# SWM341 register map
File version: 1.0
CPU: CM0 r1p0, little endian, MPU, FPU, 2 interrupt priority bits
Registers are 32-bit, read-write, no defined reset value unless marked. A register's access mark holds for its fields unless they carry their own. Offsets are from the block's base; [hi:lo] are bit positions; lines under a group give offsets from that group; {n}, {i} and the like mark numbered series; 'fields as' and 'values as' point back to an identical list.

## USBH — Registers group
Base 0x40005000; alternate view of USBD
{0x0+4i} TXBUF[{i}] (i=0..255)
{0x4000+4i} RXBUF[{i}] (i=0..255)
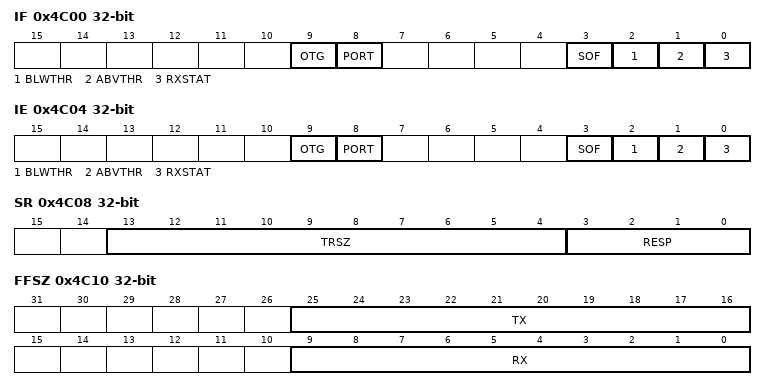
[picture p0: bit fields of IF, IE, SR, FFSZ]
0x4C00 IF
  [9] OTG, [8] PORT, [3] SOF, [2] BLWTHR, [1] ABVTHR, [0] RXSTAT
0x4C04 IE
  [9] OTG, [8] PORT, [3] SOF, [2] BLWTHR, [1] ABVTHR, [0] RXSTAT
0x4C08 SR
  [13:4] TRSZ, [3:0] RESP
0x4C0C CR
  [0] FLUSHFF
0x4C10 FFSZ
  [25:16] TX, [9:0] RX
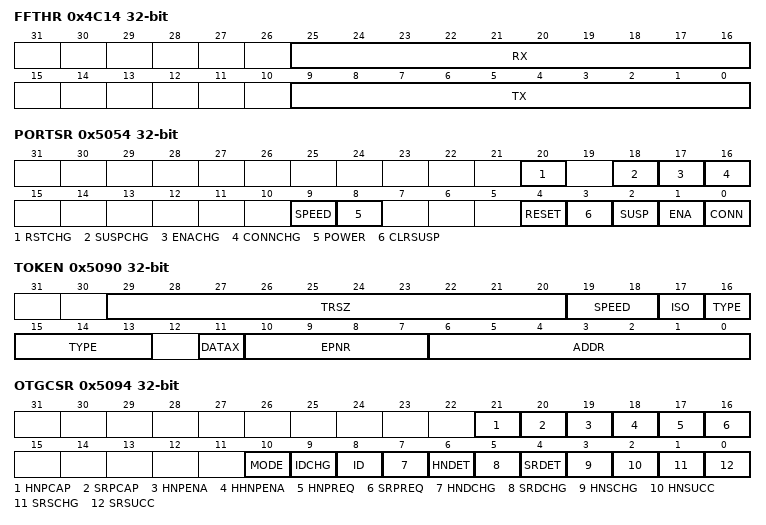
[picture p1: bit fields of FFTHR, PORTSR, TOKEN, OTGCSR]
0x4C14 FFTHR
  [25:16] RX, [9:0] TX
0x4C18 TXTRSZ
0x5034 FRAMEIV
0x5038 FRAMERM
0x503C FRAMENR
0x5054 PORTSR
  [20] RSTCHG, [18] SUSPCHG, [17] ENACHG, [16] CONNCHG, [9] SPEED, [8] POWER, [4] RESET, [3] CLRSUSP, [2] SUSP, [1] ENA, [0] CONN
0x5090 TOKEN
  [29:20] TRSZ, [19:18] SPEED, [17] ISO, [16:13] TYPE, [11] DATAX, [10:7] EPNR, [6:0] ADDR
0x5094 OTGCSR
  [21] HNPCAP, [20] SRPCAP, [19] HNPENA, [18] HHNPENA, [17] HNPREQ, [16] SRPREQ, [10] MODE, [9] IDCHG, [8] ID, [7] HNDCHG, [6] HNDET, [5] SRDCHG, [4] SRDET, [3] HNSCHG, [2] HNSUCC, [1] SRSCHG, [0] SRSUCC

## SDIO — Registers group
Base 0x40001800
0x00 DMA_MEM_ADDR
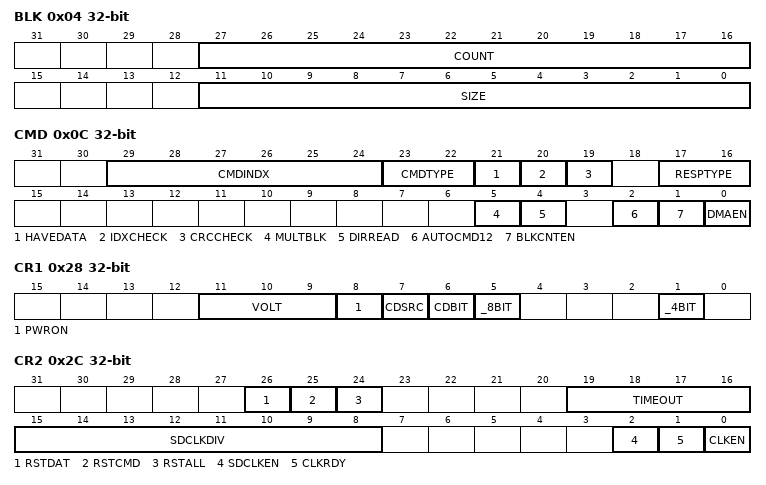
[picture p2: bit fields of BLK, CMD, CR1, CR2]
0x04 BLK
  [27:16] COUNT, [11:0] SIZE
0x08 ARG
0x0C CMD
  [29:24] CMDINDX, [23:22] CMDTYPE, [21] HAVEDATA, [20] IDXCHECK, [19] CRCCHECK, [17:16] RESPTYPE, [5] MULTBLK, [4] DIRREAD, [2] AUTOCMD12, [1] BLKCNTEN, [0] DMAEN
{0x10+4i} RESP[{i}] (i=0..3)
0x20 DATA
0x24 STAT
0x28 CR1
  [11:9] VOLT, [8] PWRON, [7] CDSRC, [6] CDBIT, [5] _8BIT, [1] _4BIT
0x2C CR2
  [26] RSTDAT, [25] RSTCMD, [24] RSTALL, [19:16] TIMEOUT, [15:8] SDCLKDIV, [2] SDCLKEN, [1] CLKRDY, [0] CLKEN
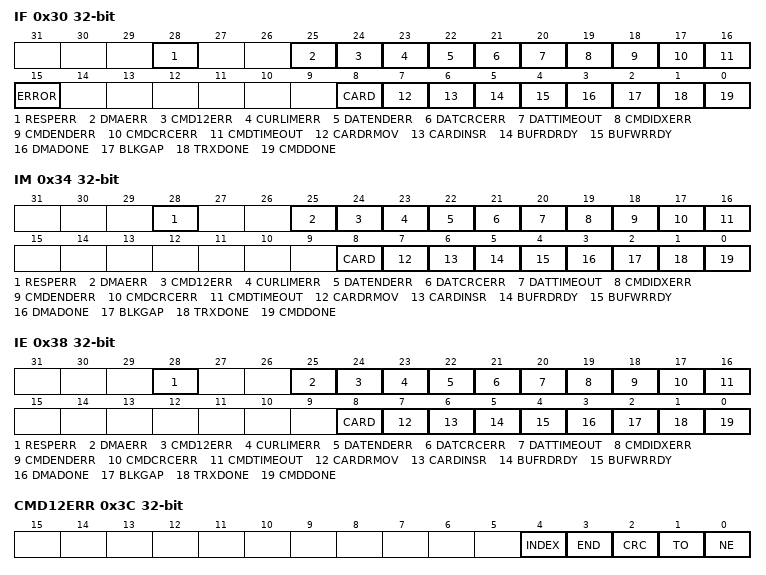
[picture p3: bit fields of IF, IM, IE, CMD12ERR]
0x30 IF
  [28] RESPERR, [25] DMAERR, [24] CMD12ERR, [23] CURLIMERR, [22] DATENDERR, [21] DATCRCERR, [20] DATTIMEOUT, [19] CMDIDXERR, [18] CMDENDERR, [17] CMDCRCERR, [16] CMDTIMEOUT, [15] ERROR, [8] CARD, [7] CARDRMOV, [6] CARDINSR, [5] BUFRDRDY, [4] BUFWRRDY, [3] DMADONE, [2] BLKGAP, [1] TRXDONE, [0] CMDDONE
0x34 IM
  [28] RESPERR, [25] DMAERR, [24] CMD12ERR, [23] CURLIMERR, [22] DATENDERR, [21] DATCRCERR, [20] DATTIMEOUT, [19] CMDIDXERR, [18] CMDENDERR, [17] CMDCRCERR, [16] CMDTIMEOUT, [8] CARD, [7] CARDRMOV, [6] CARDINSR, [5] BUFRDRDY, [4] BUFWRRDY, [3] DMADONE, [2] BLKGAP, [1] TRXDONE, [0] CMDDONE
0x38 IE
  fields as IM
0x3C CMD12ERR
  [4] INDEX, [3] END, [2] CRC, [1] TO, [0] NE

## SDRAMC — Registers group
Base 0x88000000
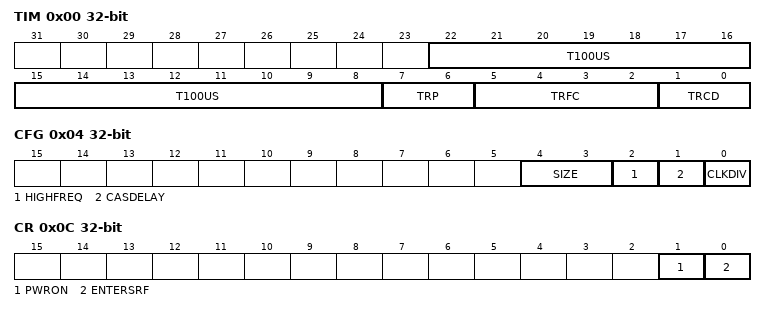
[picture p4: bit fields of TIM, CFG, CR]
0x00 TIM
  [22:8] T100US, [7:6] TRP, [5:2] TRFC, [1:0] TRCD
0x04 CFG
  [4:3] SIZE, [2] HIGHFREQ, [1] CASDELAY, [0] CLKDIV
0x08 T64
0x0C CR
  [1] PWRON, [0] ENTERSRF
0x10 SR

## DMA — Registers group
Base 0x40000800
0x00 EN
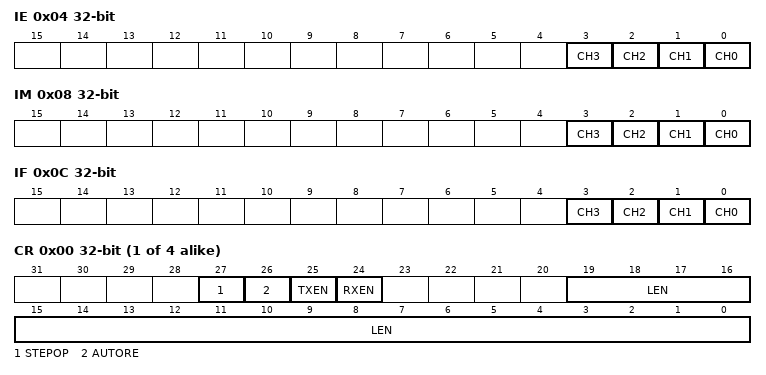
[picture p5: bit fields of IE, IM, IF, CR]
0x04 IE
  [n] CH{n} (n=0..3)
0x08 IM
  [n] CH{n} (n=0..3)
0x0C IF
  [n] CH{n} (n=0..3)
0x10 DSTSGIE
0x14 DSTSGIM
0x18 DSTSGIF
0x1C SRCSGIE
0x20 SRCSGIM
0x24 SRCSGIF
0x3C PRI
{0x40+0x40*i} CH{i} group (i=0..3) — register cluster
  0x00 CR
    [27] STEPOP, [26] AUTORE, [25] TXEN, [24] RXEN, [19:0] LEN
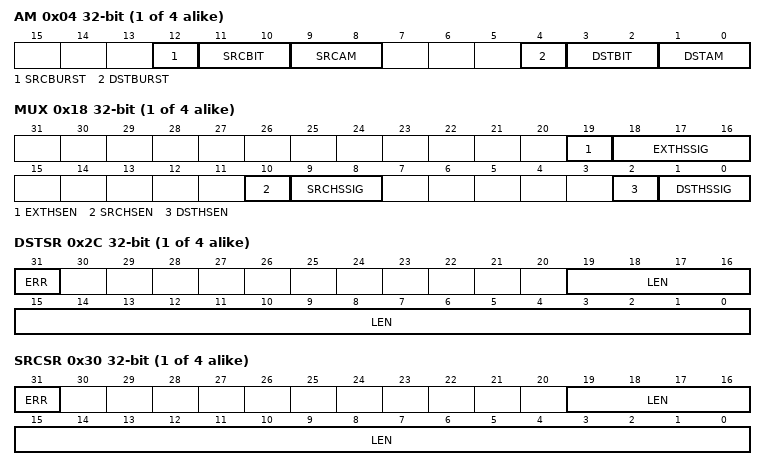
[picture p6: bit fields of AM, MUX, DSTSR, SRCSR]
  0x04 AM
    [12] SRCBURST, [11:10] SRCBIT, [9:8] SRCAM, [4] DSTBURST, [3:2] DSTBIT, [1:0] DSTAM
  0x08 DST
  {0x8+4j} DSTSGADDR{j} (j=1..3)
  0x18 MUX
    [19] EXTHSEN, [18:16] EXTHSSIG, [10] SRCHSEN, [9:8] SRCHSSIG, [2] DSTHSEN, [1:0] DSTHSSIG
  0x1C SRC
  {0x1C+4j} SRCSGADDR{j} (j=1..3)
  0x2C DSTSR ro
    [31] ERR, [19:0] LEN
  0x30 SRCSR ro
    [31] ERR, [19:0] LEN

## LCD — Registers group
Base 0x40002000
0x00 IF
0x04 IE
0x0C START
  [1] GO
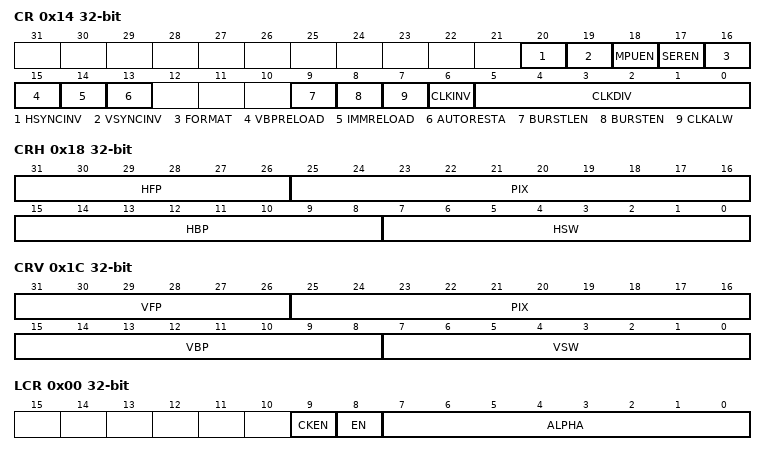
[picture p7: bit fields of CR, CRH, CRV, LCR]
0x14 CR
  [20] HSYNCINV, [19] VSYNCINV, [18] MPUEN, [17] SEREN, [16] FORMAT, [15] VBPRELOAD, [14] IMMRELOAD, [13] AUTORESTA, [9] BURSTLEN, [8] BURSTEN, [7] CLKALW, [6] CLKINV, [5:0] CLKDIV
0x18 CRH
  [31:26] HFP, [25:16] PIX, [15:8] HBP, [7:0] HSW
0x1C CRV
  [31:26] VFP, [25:16] PIX, [15:8] VBP, [7:0] VSW
0x24 BGC
0x40 L0 group — register cluster
  0x00 LCR
    [9] CKEN, [8] EN, [7:0] ALPHA
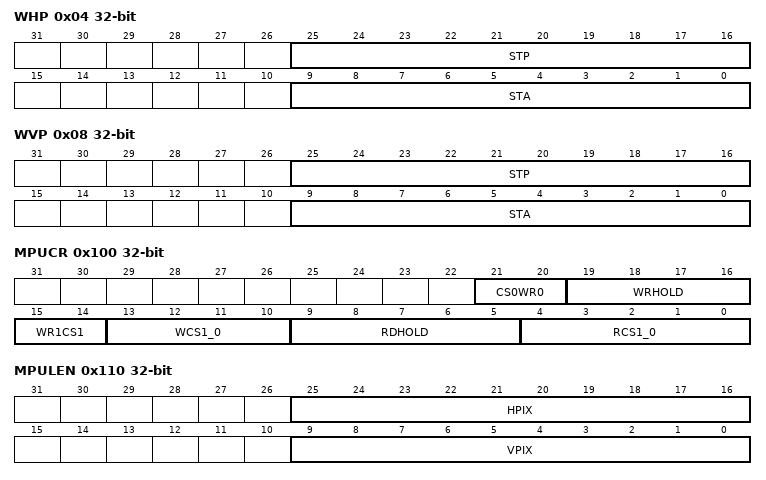
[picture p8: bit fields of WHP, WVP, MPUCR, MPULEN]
  0x04 WHP
    [25:16] STP, [9:0] STA
  0x08 WVP
    [25:16] STP, [9:0] STA
  0x0C ADDR
  0x10 LLEN
  0x14 CK
0x80 L1 group — register cluster
  0x00 LCR
    [9] CKEN, [8] EN, [7:0] ALPHA
  0x04 WHP
    [25:16] STP, [9:0] STA
  0x08 WVP
    [25:16] STP, [9:0] STA
  0x0C ADDR
  0x10 LLEN
  0x14 CK
0x100 MPUCR
  [21:20] CS0WR0, [19:16] WRHOLD, [15:14] WR1CS1, [13:10] WCS1_0, [9:5] RDHOLD, [4:0] RCS1_0
0x104 MPUIR
0x108 MPUDR
0x10C MPUAR
0x110 MPULEN
  [25:16] HPIX, [9:0] VPIX
